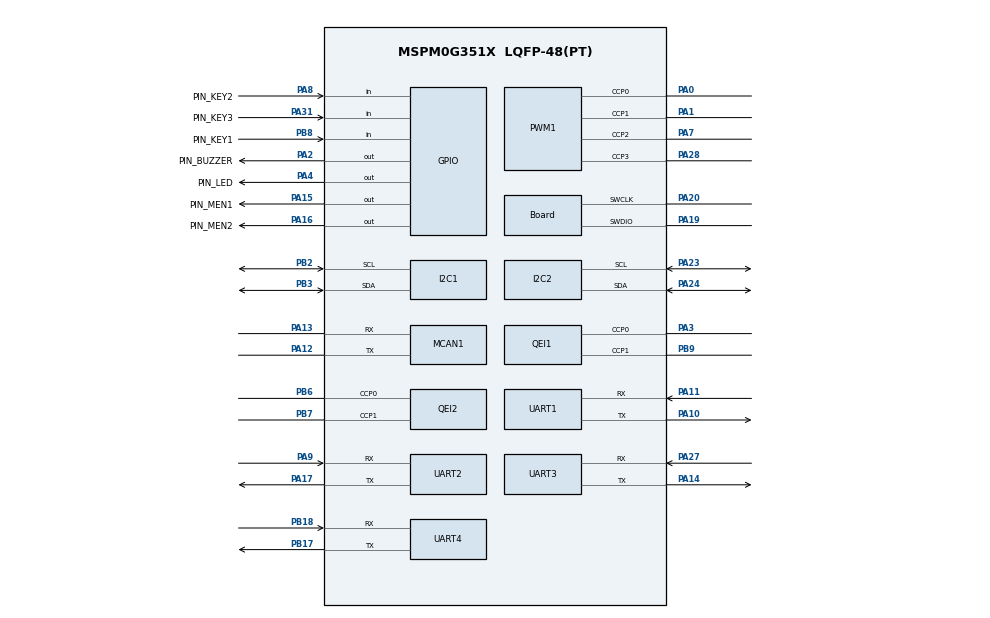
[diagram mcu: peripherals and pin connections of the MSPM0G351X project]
/**
 * @cliArgs --device "MSPM0G351X" --part "Default" --package "LQFP-48(PT)" --product "mspm0_sdk@2.10.00.04"
 * @versions {"tool":"1.27.0+4565"}
 */

/**
 * Import the modules used in this configuration.
 */
const Board         = scripting.addModule("/ti/driverlib/Board");
const GPIO          = scripting.addModule("/ti/driverlib/GPIO", {}, false);
const GPIO1         = GPIO.addInstance();
const GPIO2         = GPIO.addInstance();
const GPIO3         = GPIO.addInstance();
const GPIO4         = GPIO.addInstance();
const I2C           = scripting.addModule("/ti/driverlib/I2C", {}, false);
const I2C1          = I2C.addInstance();
const I2C2          = I2C.addInstance();
const MCAN          = scripting.addModule("/ti/driverlib/MCAN", {}, false);
const MCAN1         = MCAN.addInstance();
const PWM           = scripting.addModule("/ti/driverlib/PWM", {}, false);
const PWM1          = PWM.addInstance();
const QEI           = scripting.addModule("/ti/driverlib/QEI", {}, false);
const QEI1          = QEI.addInstance();
const QEI2          = QEI.addInstance();
const SYSCTL        = scripting.addModule("/ti/driverlib/SYSCTL");
const UART          = scripting.addModule("/ti/driverlib/UART", {}, false);
const UART1         = UART.addInstance();
const UART2         = UART.addInstance();
const UART3         = UART.addInstance();
const UART4         = UART.addInstance();
const ProjectConfig = scripting.addModule("/ti/project_config/ProjectConfig");

/**
 * Write custom configuration values to the imported modules.
 */
const divider2       = system.clockTree["HFCLK4MFPCLKDIV"];
divider2.divideValue = 10;

const divider6       = system.clockTree["PLL_CLK2X_DIV"];
divider6.divideValue = 4;

const divider9       = system.clockTree["UDIV"];
divider9.divideValue = 2;

const gate7  = system.clockTree["MFCLKGATE"];
gate7.enable = true;

const gate8  = system.clockTree["MFPCLKGATE"];
gate8.enable = true;

const multiplier2         = system.clockTree["PLL_QDIV"];
multiplier2.multiplyValue = 10;

const mux2       = system.clockTree["CANCLKMUX"];
mux2.inputSelect = "CANCLKMUX_PLLCLK1_OUT";

const mux4       = system.clockTree["EXHFMUX"];
mux4.inputSelect = "EXHFMUX_XTAL";

const mux8       = system.clockTree["HSCLKMUX"];
mux8.inputSelect = "HSCLKMUX_SYSPLL2X";

const mux10       = system.clockTree["MFPCLKMUX"];
mux10.inputSelect = "MFPCLKMUX_HFCLK";

const mux12       = system.clockTree["SYSPLLMUX"];
mux12.inputSelect = "zSYSPLLMUX_HFCLK";

const pinFunction4        = system.clockTree["HFXT"];
pinFunction4.enable       = true;
pinFunction4.HFCLKMonitor = true;
pinFunction4.inputFreq    = 16;
pinFunction4.HFXTStartup  = 255;

Board.peripheral.$assign          = "DEBUGSS";
Board.peripheral.swclkPin.$assign = "PA20";
Board.peripheral.swdioPin.$assign = "PA19";

GPIO1.$name                         = "LED";
GPIO1.port                          = "PORTA";
GPIO1.associatedPins[0].$name       = "PIN_LED";
GPIO1.associatedPins[0].assignedPin = "4";
GPIO1.associatedPins[0].pin.$assign = "PA4";

GPIO2.$name                          = "KEY";
GPIO2.associatedPins.create(3);
GPIO2.associatedPins[0].assignedPort = "PORTA";
GPIO2.associatedPins[0].assignedPin  = "31";
GPIO2.associatedPins[0].$name        = "PIN_KEY3";
GPIO2.associatedPins[0].direction    = "INPUT";
GPIO2.associatedPins[0].pin.$assign  = "PA31";
GPIO2.associatedPins[1].$name        = "PIN_KEY2";
GPIO2.associatedPins[1].assignedPort = "PORTA";
GPIO2.associatedPins[1].assignedPin  = "8";
GPIO2.associatedPins[1].direction    = "INPUT";
GPIO2.associatedPins[1].pin.$assign  = "PA8";
GPIO2.associatedPins[2].$name        = "PIN_KEY1";
GPIO2.associatedPins[2].assignedPort = "PORTB";
GPIO2.associatedPins[2].assignedPin  = "8";
GPIO2.associatedPins[2].direction    = "INPUT";
GPIO2.associatedPins[2].pin.$assign  = "PB8";

GPIO3.$name                         = "BUZZER";
GPIO3.port                          = "PORTA";
GPIO3.associatedPins[0].$name       = "PIN_BUZZER";
GPIO3.associatedPins[0].assignedPin = "2";
GPIO3.associatedPins[0].pin.$assign = "PA2";

GPIO4.$name                         = "MEN";
GPIO4.port                          = "PORTA";
GPIO4.associatedPins.create(2);
GPIO4.associatedPins[0].$name       = "PIN_MEN1";
GPIO4.associatedPins[0].assignedPin = "15";
GPIO4.associatedPins[0].pin.$assign = "PA15";
GPIO4.associatedPins[1].$name       = "PIN_MEN2";
GPIO4.associatedPins[1].assignedPin = "16";
GPIO4.associatedPins[1].pin.$assign = "PA16";

I2C1.basicEnableController             = true;
I2C1.basicControllerStandardBusSpeed   = "Fast";
I2C1.$name                             = "I2C1";
I2C1.peripheral.$assign                = "I2C1";
I2C1.peripheral.sdaPin.$assign         = "PB3";
I2C1.peripheral.sclPin.$assign         = "PB2";
I2C1.sdaPinConfig.hideOutputInversion  = scripting.forceWrite(false);
I2C1.sdaPinConfig.onlyInternalResistor = scripting.forceWrite(false);
I2C1.sdaPinConfig.passedPeripheralType = scripting.forceWrite("Digital");
I2C1.sdaPinConfig.$name                = "ti_driverlib_gpio_GPIOPinGeneric10";
I2C1.sclPinConfig.hideOutputInversion  = scripting.forceWrite(false);
I2C1.sclPinConfig.onlyInternalResistor = scripting.forceWrite(false);
I2C1.sclPinConfig.passedPeripheralType = scripting.forceWrite("Digital");
I2C1.sclPinConfig.$name                = "ti_driverlib_gpio_GPIOPinGeneric11";

I2C2.$name                             = "I2C2";
I2C2.basicEnableController             = true;
I2C2.basicControllerStandardBusSpeed   = "Fast";
I2C2.peripheral.$assign                = "I2C2";
I2C2.peripheral.sdaPin.$assign         = "PA24";
I2C2.peripheral.sclPin.$assign         = "PA23";
I2C2.sdaPinConfig.hideOutputInversion  = scripting.forceWrite(false);
I2C2.sdaPinConfig.onlyInternalResistor = scripting.forceWrite(false);
I2C2.sdaPinConfig.passedPeripheralType = scripting.forceWrite("Digital");
I2C2.sdaPinConfig.$name                = "ti_driverlib_gpio_GPIOPinGeneric12";
I2C2.sclPinConfig.hideOutputInversion  = scripting.forceWrite(false);
I2C2.sclPinConfig.onlyInternalResistor = scripting.forceWrite(false);
I2C2.sclPinConfig.passedPeripheralType = scripting.forceWrite("Digital");
I2C2.sclPinConfig.$name                = "ti_driverlib_gpio_GPIOPinGeneric13";

MCAN1.$name                    = "MCAN0";
MCAN1.fdMode                   = false;
MCAN1.spPercent                = 80;
MCAN1.desiredNomRate           = 1000;
MCAN1.stdFiltElem              = "001";
MCAN1.stdFiltType              = "00";
MCAN1.stdFiltID2               = 2047;
MCAN1.extFiltElem              = "001";
MCAN1.txBufElemSize            = "DL_MCAN_ELEM_SIZE_8BYTES";
MCAN1.rxBufElemSize            = "DL_MCAN_ELEM_SIZE_8BYTES";
MCAN1.rxFIFO0ElemSize          = "DL_MCAN_ELEM_SIZE_8BYTES";
MCAN1.rxFIFO1ElemSize          = "DL_MCAN_ELEM_SIZE_8BYTES";
MCAN1.enableInterrupt          = true;
MCAN1.interruptLine            = ["DL_MCAN_INTR_LINE_NUM_0"];
MCAN1.interruptLine0Flag       = ["DL_MCAN_INTERRUPT_RF0N","DL_MCAN_INTERRUPT_TEFN"];
MCAN1.interruptFlags           = ["DL_MCAN_INTERRUPT_RF0N","DL_MCAN_INTERRUPT_TEFN"];
MCAN1.m0interrupts             = ["DL_MCAN_MSP_INTERRUPT_LINE0"];
MCAN1.txBufNum                 = 1;
MCAN1.rxFIFO0startAddr         = 180;
MCAN1.rxFIFO0size              = 4;
MCAN1.rxFIFO0waterMark         = 1;
MCAN1.rxFIFO1startAddr         = 252;
MCAN1.rxBufStartAddr           = 284;
MCAN1.peripheral.$assign       = "CANFD0";
MCAN1.peripheral.rxPin.$assign = "PA13";
MCAN1.peripheral.txPin.$assign = "PA12";
MCAN1.txPinConfig.$name        = "ti_driverlib_gpio_GPIOPinGeneric8";
MCAN1.rxPinConfig.$name        = "ti_driverlib_gpio_GPIOPinGeneric9";

PWM1.timerStartTimer                    = true;
PWM1.timerCount                         = 2000;
PWM1.$name                              = "PWMA0_1";
PWM1.ccIndex                            = [0,1,2,3];
PWM1.PWM_CHANNEL_0.$name                = "ti_driverlib_pwm_PWMTimerCC0";
PWM1.PWM_CHANNEL_1.$name                = "ti_driverlib_pwm_PWMTimerCC1";
PWM1.ccp0PinConfig.direction            = scripting.forceWrite("OUTPUT");
PWM1.ccp0PinConfig.hideOutputInversion  = scripting.forceWrite(false);
PWM1.ccp0PinConfig.onlyInternalResistor = scripting.forceWrite(false);
PWM1.ccp0PinConfig.passedPeripheralType = scripting.forceWrite("Digital");
PWM1.ccp0PinConfig.$name                = "ti_driverlib_gpio_GPIOPinGeneric18";
PWM1.ccp1PinConfig.direction            = scripting.forceWrite("OUTPUT");
PWM1.ccp1PinConfig.hideOutputInversion  = scripting.forceWrite(false);
PWM1.ccp1PinConfig.onlyInternalResistor = scripting.forceWrite(false);
PWM1.ccp1PinConfig.passedPeripheralType = scripting.forceWrite("Digital");
PWM1.ccp1PinConfig.$name                = "ti_driverlib_gpio_GPIOPinGeneric19";
PWM1.peripheral.$assign                 = "TIMA0";
PWM1.peripheral.ccp0Pin.$assign         = "PA0";
PWM1.peripheral.ccp1Pin.$assign         = "PA1";
PWM1.peripheral.ccp2Pin.$assign         = "PA7";
PWM1.peripheral.ccp3Pin.$assign         = "PA28";
PWM1.PWM_CHANNEL_2.$name                = "ti_driverlib_pwm_PWMTimerCC2";
PWM1.PWM_CHANNEL_3.$name                = "ti_driverlib_pwm_PWMTimerCC3";
PWM1.ccp2PinConfig.$name                = "ti_driverlib_gpio_GPIOPinGeneric20";
PWM1.ccp3PinConfig.$name                = "ti_driverlib_gpio_GPIOPinGeneric21";

QEI1.$name                              = "QEI0";
QEI1.timerStartTimer                    = true;
QEI1.peripheral.$assign                 = "TIMG9";
QEI1.peripheral.ccp0Pin.$assign         = "PA3";
QEI1.peripheral.ccp1Pin.$assign         = "PB9";
QEI1.ccp0PinConfig.hideOutputInversion  = scripting.forceWrite(false);
QEI1.ccp0PinConfig.onlyInternalResistor = scripting.forceWrite(false);
QEI1.ccp0PinConfig.passedPeripheralType = scripting.forceWrite("Digital");
QEI1.ccp0PinConfig.$name                = "ti_driverlib_gpio_GPIOPinGeneric14";
QEI1.ccp1PinConfig.hideOutputInversion  = scripting.forceWrite(false);
QEI1.ccp1PinConfig.onlyInternalResistor = scripting.forceWrite(false);
QEI1.ccp1PinConfig.passedPeripheralType = scripting.forceWrite("Digital");
QEI1.ccp1PinConfig.$name                = "ti_driverlib_gpio_GPIOPinGeneric15";

QEI2.$name                              = "QEI1";
QEI2.timerStartTimer                    = true;
QEI2.peripheral.$assign                 = "TIMG8";
QEI2.peripheral.ccp0Pin.$assign         = "PB6";
QEI2.peripheral.ccp1Pin.$assign         = "PB7";
QEI2.ccp0PinConfig.hideOutputInversion  = scripting.forceWrite(false);
QEI2.ccp0PinConfig.onlyInternalResistor = scripting.forceWrite(false);
QEI2.ccp0PinConfig.passedPeripheralType = scripting.forceWrite("Digital");
QEI2.ccp0PinConfig.$name                = "ti_driverlib_gpio_GPIOPinGeneric16";
QEI2.ccp1PinConfig.hideOutputInversion  = scripting.forceWrite(false);
QEI2.ccp1PinConfig.onlyInternalResistor = scripting.forceWrite(false);
QEI2.ccp1PinConfig.passedPeripheralType = scripting.forceWrite("Digital");
QEI2.ccp1PinConfig.$name                = "ti_driverlib_gpio_GPIOPinGeneric17";

SYSCTL.forceDefaultClkConfig = true;
SYSCTL.clockTreeEn           = true;

UART1.$name                             = "UART0";
UART1.targetBaudRate                    = 115200;
UART1.enableFIFO                        = true;
UART1.rxFifoThreshold                   = "DL_UART_RX_FIFO_LEVEL_FULL";
UART1.txFifoThreshold                   = "DL_UART_TX_FIFO_LEVEL_EMPTY";
UART1.enabledDMATXTriggers              = "DL_UART_DMA_INTERRUPT_TX";
UART1.enabledInterrupts                 = ["DMA_DONE_TX","RX"];
UART1.peripheral.$assign                = "UART0";
UART1.peripheral.rxPin.$assign          = "PA11";
UART1.peripheral.txPin.$assign          = "PA10";
UART1.txPinConfig.direction             = scripting.forceWrite("OUTPUT");
UART1.txPinConfig.hideOutputInversion   = scripting.forceWrite(false);
UART1.txPinConfig.onlyInternalResistor  = scripting.forceWrite(false);
UART1.txPinConfig.passedPeripheralType  = scripting.forceWrite("Digital");
UART1.txPinConfig.$name                 = "ti_driverlib_gpio_GPIOPinGeneric0";
UART1.rxPinConfig.hideOutputInversion   = scripting.forceWrite(false);
UART1.rxPinConfig.onlyInternalResistor  = scripting.forceWrite(false);
UART1.rxPinConfig.passedPeripheralType  = scripting.forceWrite("Digital");
UART1.rxPinConfig.$name                 = "ti_driverlib_gpio_GPIOPinGeneric1";
UART1.DMA_CHANNEL_TX.$name              = "DMA_CH0";
UART1.DMA_CHANNEL_TX.addressMode        = "b2f";
UART1.DMA_CHANNEL_TX.srcLength          = "BYTE";
UART1.DMA_CHANNEL_TX.dstLength          = "BYTE";
UART1.DMA_CHANNEL_TX.peripheral.$assign = "DMA_CH0";

UART2.$name                             = "UART1";
UART2.targetBaudRate                    = 115200;
UART2.enableFIFO                        = true;
UART2.rxFifoThreshold                   = "DL_UART_RX_FIFO_LEVEL_FULL";
UART2.txFifoThreshold                   = "DL_UART_TX_FIFO_LEVEL_EMPTY";
UART2.enabledInterrupts                 = ["DMA_DONE_TX","RX"];
UART2.enabledDMATXTriggers              = "DL_UART_DMA_INTERRUPT_TX";
UART2.peripheral.$assign                = "UART1";
UART2.peripheral.rxPin.$assign          = "PA9";
UART2.peripheral.txPin.$assign          = "PA17";
UART2.txPinConfig.direction             = scripting.forceWrite("OUTPUT");
UART2.txPinConfig.hideOutputInversion   = scripting.forceWrite(false);
UART2.txPinConfig.onlyInternalResistor  = scripting.forceWrite(false);
UART2.txPinConfig.passedPeripheralType  = scripting.forceWrite("Digital");
UART2.txPinConfig.$name                 = "ti_driverlib_gpio_GPIOPinGeneric2";
UART2.rxPinConfig.hideOutputInversion   = scripting.forceWrite(false);
UART2.rxPinConfig.onlyInternalResistor  = scripting.forceWrite(false);
UART2.rxPinConfig.passedPeripheralType  = scripting.forceWrite("Digital");
UART2.rxPinConfig.$name                 = "ti_driverlib_gpio_GPIOPinGeneric3";
UART2.DMA_CHANNEL_TX.$name              = "DMA_CH1";
UART2.DMA_CHANNEL_TX.addressMode        = "b2f";
UART2.DMA_CHANNEL_TX.srcLength          = "BYTE";
UART2.DMA_CHANNEL_TX.dstLength          = "BYTE";
UART2.DMA_CHANNEL_TX.peripheral.$assign = "DMA_CH1";

UART3.$name                             = "UART3";
UART3.targetBaudRate                    = 115200;
UART3.enableFIFO                        = true;
UART3.rxFifoThreshold                   = "DL_UART_RX_FIFO_LEVEL_FULL";
UART3.txFifoThreshold                   = "DL_UART_TX_FIFO_LEVEL_EMPTY";
UART3.enabledInterrupts                 = ["DMA_DONE_TX","RX"];
UART3.enabledDMATXTriggers              = "DL_UART_DMA_INTERRUPT_TX";
UART3.peripheral.$assign                = "UART3";
UART3.peripheral.rxPin.$assign          = "PA27";
UART3.peripheral.txPin.$assign          = "PA14";
UART3.txPinConfig.direction             = scripting.forceWrite("OUTPUT");
UART3.txPinConfig.hideOutputInversion   = scripting.forceWrite(false);
UART3.txPinConfig.onlyInternalResistor  = scripting.forceWrite(false);
UART3.txPinConfig.passedPeripheralType  = scripting.forceWrite("Digital");
UART3.txPinConfig.$name                 = "ti_driverlib_gpio_GPIOPinGeneric4";
UART3.rxPinConfig.hideOutputInversion   = scripting.forceWrite(false);
UART3.rxPinConfig.onlyInternalResistor  = scripting.forceWrite(false);
UART3.rxPinConfig.passedPeripheralType  = scripting.forceWrite("Digital");
UART3.rxPinConfig.$name                 = "ti_driverlib_gpio_GPIOPinGeneric5";
UART3.DMA_CHANNEL_TX.$name              = "DMA_CH2";
UART3.DMA_CHANNEL_TX.addressMode        = "b2f";
UART3.DMA_CHANNEL_TX.srcLength          = "BYTE";
UART3.DMA_CHANNEL_TX.dstLength          = "BYTE";
UART3.DMA_CHANNEL_TX.peripheral.$assign = "DMA_CH2";

UART4.$name                             = "UART4";
UART4.targetBaudRate                    = 115200;
UART4.enableFIFO                        = true;
UART4.rxFifoThreshold                   = "DL_UART_RX_FIFO_LEVEL_FULL";
UART4.txFifoThreshold                   = "DL_UART_TX_FIFO_LEVEL_EMPTY";
UART4.enabledInterrupts                 = ["DMA_DONE_TX","RX"];
UART4.enabledDMATXTriggers              = "DL_UART_DMA_INTERRUPT_TX";
UART4.peripheral.$assign                = "UART4";
UART4.peripheral.rxPin.$assign          = "PB18";
UART4.peripheral.txPin.$assign          = "PB17";
UART4.txPinConfig.direction             = scripting.forceWrite("OUTPUT");
UART4.txPinConfig.hideOutputInversion   = scripting.forceWrite(false);
UART4.txPinConfig.onlyInternalResistor  = scripting.forceWrite(false);
UART4.txPinConfig.passedPeripheralType  = scripting.forceWrite("Digital");
UART4.txPinConfig.$name                 = "ti_driverlib_gpio_GPIOPinGeneric6";
UART4.rxPinConfig.hideOutputInversion   = scripting.forceWrite(false);
UART4.rxPinConfig.onlyInternalResistor  = scripting.forceWrite(false);
UART4.rxPinConfig.passedPeripheralType  = scripting.forceWrite("Digital");
UART4.rxPinConfig.$name                 = "ti_driverlib_gpio_GPIOPinGeneric7";
UART4.DMA_CHANNEL_TX.$name              = "DMA_CH3";
UART4.DMA_CHANNEL_TX.addressMode        = "b2f";
UART4.DMA_CHANNEL_TX.srcLength          = "BYTE";
UART4.DMA_CHANNEL_TX.dstLength          = "BYTE";
UART4.DMA_CHANNEL_TX.peripheral.$assign = "DMA_CH3";

ProjectConfig.migrationCondition = true;

/**
 * Pinmux solution for unlocked pins/peripherals. This ensures that minor changes to the automatic solver in a future
 * version of the tool will not impact the pinmux you originally saw.  These lines can be completely deleted in order to
 * re-solve from scratch.
 */
pinFunction4.peripheral.$suggestSolution           = "SYSCTL";
pinFunction4.peripheral.hfxInPin.$suggestSolution  = "PA5";
pinFunction4.peripheral.hfxOutPin.$suggestSolution = "PA6";
